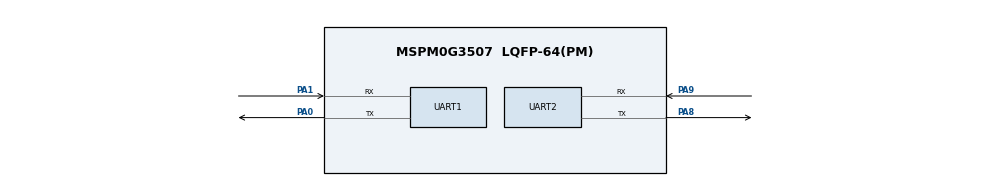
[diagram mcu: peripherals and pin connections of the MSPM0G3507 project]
/**
 * These arguments were used when this file was generated. They will be automatically applied on subsequent loads
 * via the GUI or CLI. Run CLI with '--help' for additional information on how to override these arguments.
 * @cliArgs --device "MSPM0G350X" --part "Default" --package "LQFP-64(PM)" --product "mspm0_sdk@2.05.01.00"
 * @v2CliArgs --device "MSPM0G3507" --package "LQFP-64(PM)" --product "mspm0_sdk@2.05.01.00"
 * @versions {"tool":"1.24.1+4189"}
 */

/**
 * Import the modules used in this configuration.
 */
const ADC12   = scripting.addModule("/ti/driverlib/ADC12", {}, false);
const ADC121  = ADC12.addInstance();
const GPIO    = scripting.addModule("/ti/driverlib/GPIO", {}, false);
const GPIO1   = GPIO.addInstance();
const GPIO2   = GPIO.addInstance();
const PWM     = scripting.addModule("/ti/driverlib/PWM", {}, false);
const PWM1    = PWM.addInstance();
const SYSCTL  = scripting.addModule("/ti/driverlib/SYSCTL");
const SYSTICK = scripting.addModule("/ti/driverlib/SYSTICK");
const TIMER   = scripting.addModule("/ti/driverlib/TIMER", {}, false);
const TIMER1  = TIMER.addInstance();
const TIMER2  = TIMER.addInstance();
const UART    = scripting.addModule("/ti/driverlib/UART", {}, false);
const UART1   = UART.addInstance();
const UART2   = UART.addInstance();

/**
 * Write custom configuration values to the imported modules.
 */
const divider6       = system.clockTree["PLL_CLK2X_DIV"];
divider6.divideValue = 4;

const divider7       = system.clockTree["PLL_PDIV"];
divider7.divideValue = 2;

const divider9       = system.clockTree["UDIV"];
divider9.divideValue = 2;

const multiplier2         = system.clockTree["PLL_QDIV"];
multiplier2.multiplyValue = 10;

const mux8       = system.clockTree["HSCLKMUX"];
mux8.inputSelect = "HSCLKMUX_SYSPLL2X";

ADC121.$name                 = "ADC12_0";
ADC121.repeatMode            = true;
ADC121.samplingOperationMode = "sequence";
ADC121.endAdd                = 1;
ADC121.adcMem1chansel        = "DL_ADC12_INPUT_CHAN_1";
ADC121.sampleTime0           = "1 ms";
ADC121.enabledInterrupts     = ["DL_ADC12_INTERRUPT_MEM1_RESULT_LOADED"];
ADC121.adcPin0Config.$name   = "ti_driverlib_gpio_GPIOPinGeneric4";
ADC121.peripheral.$assign    = "ADC0";
ADC121.adcPin1Config.$name   = "ti_driverlib_gpio_GPIOPinGeneric5";

const Board = scripting.addModule("/ti/driverlib/Board", {}, false);

GPIO1.port                               = "PORTB";
GPIO1.$name                              = "LED";
GPIO1.associatedPins[0].initialValue     = "SET";
GPIO1.associatedPins[0].internalResistor = "PULL_DOWN";
GPIO1.associatedPins[0].$name            = "D1";
GPIO1.associatedPins[0].assignedPin      = "14";

GPIO2.$name                              = "KEY";
GPIO2.port                               = "PORTB";
GPIO2.associatedPins[0].direction        = "INPUT";
GPIO2.associatedPins[0].assignedPin      = "21";
GPIO2.associatedPins[0].$name            = "S2";
GPIO2.associatedPins[0].internalResistor = "PULL_UP";

PWM1.$name                 = "PWM_0";
PWM1.clockPrescale         = 32;
PWM1.timerStartTimer       = true;
PWM1.pwmMode               = "EDGE_ALIGN_UP";
PWM1.peripheral.$assign    = "TIMA1";
PWM1.PWM_CHANNEL_0.$name   = "ti_driverlib_pwm_PWMTimerCC0";
PWM1.PWM_CHANNEL_0.ccValue = 500;
PWM1.PWM_CHANNEL_1.$name   = "ti_driverlib_pwm_PWMTimerCC1";
PWM1.PWM_CHANNEL_1.ccValue = 500;
PWM1.ccp0PinConfig.$name   = "ti_driverlib_gpio_GPIOPinGeneric0";
PWM1.ccp1PinConfig.$name   = "ti_driverlib_gpio_GPIOPinGeneric1";

SYSCTL.forceDefaultClkConfig = true;
SYSCTL.clockTreeEn           = true;
scripting.suppress("For best practices when the CPUCLK is running at 32MHz and above, clear the flash status bit using DL_FlashCTL_executeClearStatus\\(\\) before executing any flash operation\\. Otherwise there may be false positives\\.", SYSCTL);

SYSTICK.periodEnable      = true;
SYSTICK.interruptEnable   = true;
SYSTICK.interruptPriority = "0";
SYSTICK.systickEnable     = true;
SYSTICK.period            = 80000;

TIMER1.$name              = "TIMER_1ms";
TIMER1.timerMode          = "PERIODIC_UP";
TIMER1.timerPeriod        = "1 ms";
TIMER1.timerStartTimer    = true;
TIMER1.interrupts         = ["ZERO"];
TIMER1.timerClkDiv        = 2;
TIMER1.peripheral.$assign = "TIMA0";

TIMER2.$name            = "TIMER_1s";
TIMER2.timerMode        = "PERIODIC_UP";
TIMER2.timerClkDiv      = 8;
TIMER2.timerClkPrescale = 200;
TIMER2.timerPeriod      = "1s";
TIMER2.timerStartTimer  = true;
TIMER2.interrupts       = ["ZERO"];

UART1.$name                    = "UART_0";
UART1.enabledInterrupts        = ["RX"];
UART1.peripheral.rxPin.$assign = "PA1";
UART1.peripheral.txPin.$assign = "PA0";
UART1.txPinConfig.$name        = "ti_driverlib_gpio_GPIOPinGeneric2";
UART1.rxPinConfig.$name        = "ti_driverlib_gpio_GPIOPinGeneric3";

UART2.$name                    = "UART_1";
UART2.enabledInterrupts        = ["RX"];
UART2.peripheral.rxPin.$assign = "PA9";
UART2.peripheral.txPin.$assign = "PA8";
UART2.txPinConfig.$name        = "ti_driverlib_gpio_GPIOPinGeneric6";
UART2.rxPinConfig.$name        = "ti_driverlib_gpio_GPIOPinGeneric7";

/**
 * Pinmux solution for unlocked pins/peripherals. This ensures that minor changes to the automatic solver in a future
 * version of the tool will not impact the pinmux you originally saw.  These lines can be completely deleted in order to
 * re-solve from scratch.
 */
ADC121.peripheral.adcPin0.$suggestSolution   = "PA27";
ADC121.peripheral.adcPin1.$suggestSolution   = "PA26";
Board.peripheral.$suggestSolution            = "DEBUGSS";
Board.peripheral.swclkPin.$suggestSolution   = "PA20";
Board.peripheral.swdioPin.$suggestSolution   = "PA19";
GPIO1.associatedPins[0].pin.$suggestSolution = "PB14";
GPIO2.associatedPins[0].pin.$suggestSolution = "PB21";
PWM1.peripheral.ccp0Pin.$suggestSolution     = "PA10";
PWM1.peripheral.ccp1Pin.$suggestSolution     = "PA11";
TIMER2.peripheral.$suggestSolution           = "TIMG0";
UART1.peripheral.$suggestSolution            = "UART0";
UART2.peripheral.$suggestSolution            = "UART1";
